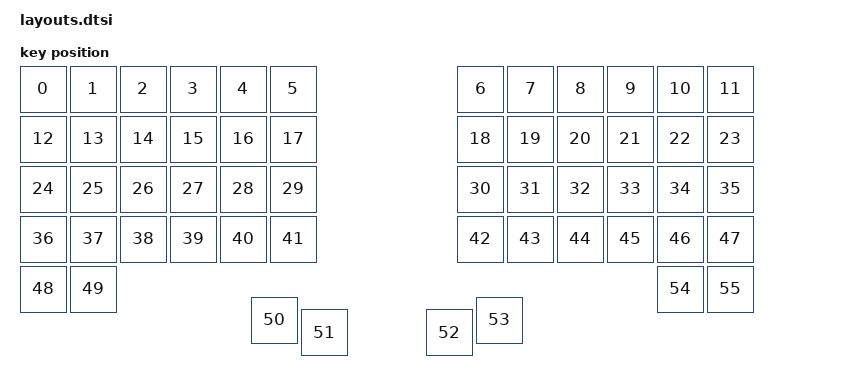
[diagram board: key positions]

#include <physical_layouts.dtsi>
/ {
    physical_layout0: physical_layout0 {
        compatible = "zmk,physical-layout";
        display-name = "Layout";
        keys
            = <&key_physical_attrs 100 100 0 13 0 0 0>
			,<&key_physical_attrs 100 100 100 13 0 0 0>
			,<&key_physical_attrs 100 100 200 13 0 0 0>
			,<&key_physical_attrs 100 100 300 13 0 0 0>
			,<&key_physical_attrs 100 100 400 13 0 0 0>
			,<&key_physical_attrs 100 100 500 13 0 0 0>
			,<&key_physical_attrs 100 100 875 13 0 0 0>
			,<&key_physical_attrs 100 100 975 13 0 0 0>
			,<&key_physical_attrs 100 100 1075 13 0 0 0>
			,<&key_physical_attrs 100 100 1175 13 0 0 0>
			,<&key_physical_attrs 100 100 1275 13 0 0 0>
			,<&key_physical_attrs 100 100 1375 13 0 0 0>
			,<&key_physical_attrs 100 100 0 113 0 0 0>
			,<&key_physical_attrs 100 100 100 113 0 0 0>
			,<&key_physical_attrs 100 100 200 113 0 0 0>
			,<&key_physical_attrs 100 100 300 113 0 0 0>
			,<&key_physical_attrs 100 100 400 113 0 0 0>
			,<&key_physical_attrs 100 100 500 113 0 0 0>
			,<&key_physical_attrs 100 100 875 113 0 0 0>
			,<&key_physical_attrs 100 100 975 113 0 0 0>
			,<&key_physical_attrs 100 100 1075 113 0 0 0>
			,<&key_physical_attrs 100 100 1175 113 0 0 0>
			,<&key_physical_attrs 100 100 1275 113 0 0 0>
			,<&key_physical_attrs 100 100 1375 113 0 0 0>
			,<&key_physical_attrs 100 100 0 213 0 0 0>
			,<&key_physical_attrs 100 100 100 213 0 0 0>
			,<&key_physical_attrs 100 100 200 213 0 0 0>
			,<&key_physical_attrs 100 100 300 213 0 0 0>
			,<&key_physical_attrs 100 100 400 213 0 0 0>
			,<&key_physical_attrs 100 100 500 213 0 0 0>
			,<&key_physical_attrs 100 100 875 213 0 0 0>
			,<&key_physical_attrs 100 100 975 213 0 0 0>
			,<&key_physical_attrs 100 100 1075 213 0 0 0>
			,<&key_physical_attrs 100 100 1175 213 0 0 0>
			,<&key_physical_attrs 100 100 1275 213 0 0 0>
			,<&key_physical_attrs 100 100 1375 213 0 0 0>
			,<&key_physical_attrs 100 100 0 313 0 0 0>
			,<&key_physical_attrs 100 100 100 313 0 0 0>
			,<&key_physical_attrs 100 100 200 313 0 0 0>
			,<&key_physical_attrs 100 100 300 313 0 0 0>
			,<&key_physical_attrs 100 100 400 313 0 0 0>
			,<&key_physical_attrs 100 100 500 313 0 0 0>
			,<&key_physical_attrs 100 100 875 313 0 0 0>
			,<&key_physical_attrs 100 100 975 313 0 0 0>
			,<&key_physical_attrs 100 100 1075 313 0 0 0>
			,<&key_physical_attrs 100 100 1175 313 0 0 0>
			,<&key_physical_attrs 100 100 1275 313 0 0 0>
			,<&key_physical_attrs 100 100 1375 313 0 0 0>
			,<&key_physical_attrs 100 100 0 413 0 0 0>
			,<&key_physical_attrs 100 100 100 413 0 0 0>
			,<&key_physical_attrs 100 100 463 475 0 0 0>
			,<&key_physical_attrs 100 100 563 500 0 0 0>
			,<&key_physical_attrs 100 100 813 500 0 0 0>
			,<&key_physical_attrs 100 100 913 475 0 0 0>
			,<&key_physical_attrs 100 100 1275 413 0 0 0>
			,<&key_physical_attrs 100 100 1375 413 0 0 0>
            ;
    };
};
    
